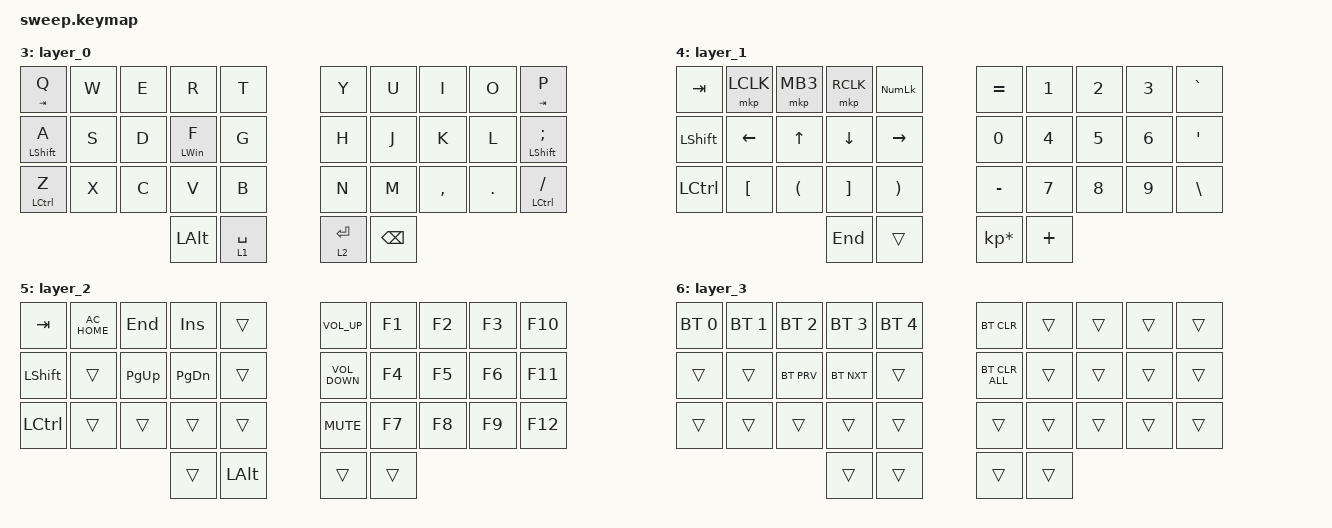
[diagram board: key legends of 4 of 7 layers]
#include <behaviors.dtsi>
#include <dt-bindings/zmk/bt.h>
#include <dt-bindings/zmk/keys.h>
#include <dt-bindings/zmk/mouse.h>

&mt {
    flavor = "tap-preferred";
    tapping_term_ms = <200>;
};

/ {
    combos {
        compatible = "zmk,combos";

        esc {
            bindings = <&kp ESCAPE>;
            key-positions = <20 21>;
        };

        delete {/*
 * Copyright (c) 2020 The ZMK Contributors
 *
 * SPDX-License-Identifier: MIT
 */

#include <behaviors.dtsi>
#include <dt-bindings/zmk/keys.h>

#define DEFAULT 0
#define LOWER  1
#define RAISE  2

/* NOTE: At the time of the creation of this keymap, there are no specified codes for 'eisuu' and 'kana' input in ZMK.
However, 'LANG1' and 'LANG2' are fully-functioning candidates for 'kana' and 'eisuu' input respectively.
As such, those are in use within the default layer at this time.*/

/ {
    keymap {
        compatible = "zmk,keymap";

        default_layer {
            // ---------------------------------------------------------------------------------------------------------------------------------
            // | GRAVE  |   1    |   2    |   3    |   4    |   5    |  LBKT  |                    |  RBKT  |   6    |   7    |   8    |   9    |   0    |  DEL   |
            // |  TAB   |   Q    |   W    |   E    |   R    |   T    |  LBKT  |                    |  RBKT  |   Y    |   U    |   I    |   O    |   P    |  BSPC  |
            // |  CTRL  |   A    |   S    |   D    |   F    |   G    |                                      |   H    |   J    |   K    |   L    |   ;    |   '    |
            // |  SHIFT |   Z    |   X    |   C    |   V    |   B    |  LBKT  |                    |  RBKT  |   N    |   M    |   ,    |   .    |   /    |  RET   |

            bindings = <
&kp ESC     &kp Q  &kp W  &kp F  &kp P  &kp G      &kp LEFT_WIN  &kp CAPS   &kp J     &kp L  &kp U      &kp Y    &kp SEMI      &kp RALT
&kp TAB     &kp A  &kp R  &kp S  &kp T  &kp D      &kp LALT      &kp PSCRN  &kp H     &kp N  &kp E      &kp I    &kp O         &kp SQT
&kp LSHIFT  &kp Z  &kp X  &kp C  &kp V  &kp B                               &kp K     &kp M  &kp COMMA  &kp DOT  &kp KP_SLASH  &kp DEL
                                 &mo 1  &kp LCTRL  &kp SPACE     &kp ENTER  &kp BSPC  &mo 2
            >;
        };

        lower_layer {
            // ---------------------------------------------------------------------------------------------------------------------------------
            // |      |      |      |      |      |      |                                  |      |      |      |      |      |      |
            // |  ~   |  !   |  @   |  #   |  $   |  %   |                                  |  ^   |  &   |  *   |  (   |  )   |      |
            // |      |      |      |      |      |      |                                  |      |  _   |  +   |  {   |  }   | PIPE |
            // |      |      |      |      |      |      |  (   |                    |  )   |      |      |      | HOME | END  |      |
            // |      |      |      |      |      |      |      |                    |      |      |      |      |      |      |      |

            bindings = <
&kp ESC         &trans     &kp KP_N1        &kp KP_NUMBER_2  &kp KP_N3  &kp PERCENT       &kp LWIN   &kp CAPS   &kp KP_EQUAL     &kp HOME       &kp UP    &kp END    &trans    &kp RIGHT_ALT
&kp TAB         &kp KP_N0  &kp KP_NUMBER_4  &kp KP_NUMBER_5  &kp KP_N6  &kp KP_SUBTRACT   &kp LALT   &kp PSCRN  &kp KP_PLUS      &kp LEFT       &kp DOWN  &kp RIGHT  &kp RPAR  &trans
&kp LEFT_SHIFT  &trans     &kp KP_N7        &kp KP_NUMBER_8  &kp KP_N9  &kp KP_DIVIDE                           &kp KP_ASTERISK  &kp BACKSLASH  &kp AT    &trans     &trans    &kp DELETE
                                                             &trans     &kp LEFT_CONTROL  &kp SPACE  &kp ENTER  &kp BACKSPACE    &trans
            >;
        };

        raise_layer {
            bindings = <
&kp ESC         &kp F1  &kp F2  &kp F3  &kp LEFT_BRACE        &kp RIGHT_BRACE        &kp LWIN   &kp CAPS   &kp EXCL       &kp AMPS   &kp PIPE       &kp F10    &kp F11  &kp RIGHT_ALT
&kp TAB         &kp F4  &kp F5  &kp F6  &kp LEFT_PARENTHESIS  &kp RIGHT_PARENTHESIS  &kp LALT   &kp PSCRN  &kp DOLLAR     &kp UNDER  &kp TILDE      &kp CARET  &kp F12  &trans
&kp LEFT_SHIFT  &kp F7  &kp F8  &kp F9  &kp LEFT_BRACKET      &kp RIGHT_BRACKET                            &kp HASH       &kp PG_UP  &kp PAGE_DOWN  &trans     &trans   &kp DELETE
                                        &trans                &kp LEFT_CONTROL       &kp SPACE  &kp ENTER  &kp BACKSPACE  &trans
            >;
        };
    };
};
            bindings = <&kp DEL>;
            key-positions = <16 17>;
        };

        backspace {
            bindings = <&kp BACKSPACE>;
            key-positions = <12 13>;
        };

        combodelete {
            bindings = <&kp LC(BACKSPACE)>;
            key-positions = <0 4>;
        };
    };

    keymap {
        compatible = "zmk,keymap";

        layer_0 {
            bindings = <
&mt TAB Q           &kp W  &kp E  &kp R           &kp T          &kp Y        &kp U     &kp I      &kp O    &mt TAB P
&mt LEFT_SHIFT A    &kp S  &kp D  &mt LEFT_WIN F  &kp G          &kp H        &kp J     &kp K      &kp L    &mt LEFT_SHIFT SEMICOLON
&mt LEFT_CONTROL Z  &kp X  &kp C  &kp V           &kp B          &kp N        &kp M     &kp COMMA  &kp DOT  &mt LEFT_CONTROL SLASH
                                  &kp LEFT_ALT    &lt 1 SPACE    &lt 2 ENTER  &kp BSPC
            >;
        };

        layer_1 {
            bindings = <
&kp TAB    &mkp LCLK         &mkp MB3              &mkp RCLK          &kp KP_NUMLOCK           &kp EQUAL        &kp NUMBER_1  &kp NUMBER_2  &kp NUMBER_3  &kp GRAVE
&kp LSHFT  &kp LEFT          &kp UP_ARROW          &kp DOWN_ARROW     &kp RIGHT_ARROW          &kp N0           &kp NUMBER_4  &kp N5        &kp NUMBER_6  &kp APOS
&kp LCTRL  &kp LEFT_BRACKET  &kp LEFT_PARENTHESIS  &kp RIGHT_BRACKET  &kp RIGHT_PARENTHESIS    &kp MINUS        &kp N7        &kp N8        &kp N9        &kp BSLH
                                                   &kp END            &trans                   &kp KP_MULTIPLY  &kp PLUS
            >;
        };

        layer_2 {
            bindings = <
&kp TAB    &kp C_AC_HOME  &kp END      &kp INS        &trans          &kp C_VOLUME_UP    &kp F1  &kp F2  &kp F3  &kp F10
&kp LSHFT  &trans         &kp PAGE_UP  &kp PAGE_DOWN  &trans          &kp C_VOLUME_DOWN  &kp F4  &kp F5  &kp F6  &kp F11
&kp LCTRL  &trans         &trans       &trans         &trans          &kp K_MUTE         &kp F7  &kp F8  &kp F9  &kp F12
                                       &trans         &kp LEFT_ALT    &trans             &trans
            >;
        };

        layer_3 {
            bindings = <
&bt BT_SEL 0  &bt BT_SEL 1  &bt BT_SEL 2  &bt BT_SEL 3  &bt BT_SEL 4    &bt BT_CLR      &trans  &trans  &trans  &trans
&trans        &trans        &bt BT_PRV    &bt BT_NXT    &trans          &bt BT_CLR_ALL  &trans  &trans  &trans  &trans
&trans        &trans        &trans        &trans        &trans          &trans          &trans  &trans  &trans  &trans
                                          &trans        &trans          &trans          &trans
            >;
        };
    };

    conditional_layers {
        compatible = "zmk,conditional-layers";

        layerbt {
            if-layers = <1 2>;
            then-layer = <3>;
        };
    };
};
